# G32R501 register map
Vendor: Geehy Semiconductor Co., Ltd.; Series: G32R5; File version: 1.0
CPU: CM55 r0p1, little endian, MPU, FPU, double-precision FPU, DSP, VTOR, 4 interrupt priority bits
Registers are 32-bit, read-write, reset 0x0 unless marked. A register's access mark holds for its fields unless they carry their own. Offsets are from the block's base; [hi:lo] are bit positions; {n}, {i} and the like mark numbered series; 'fields as' and 'values as' point back to an identical list.

## CANA — CAN
Base 0x50002000
Same registers: CANB 0x50101800
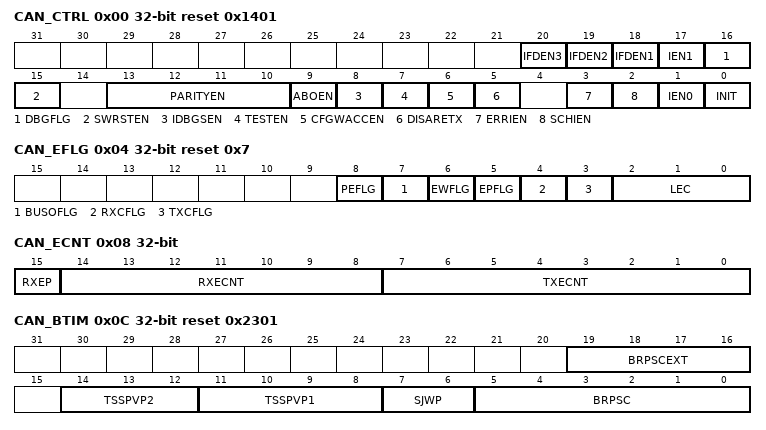
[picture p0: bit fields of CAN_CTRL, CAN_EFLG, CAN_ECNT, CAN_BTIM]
0x00 CAN_CTRL access per field reset 0x1401 — Control Register
  [20] IFDEN3 rw — IF3 DMA request line Enable
  [19] IFDEN2 rw — IF2 DMA request line Enable
  [18] IFDEN1 rw — IF1 DMA request line Enable
  [17] IEN1 rw — Interrupt line 1 Enable
  [16] DBGFLG ro — Debug Mode Flag
  [15] SWRSTEN rw — Software Reset Enable
  [13:10] PARITYEN rw — Parity Enable
  [9] ABOEN ro — Auto-Bus-On Enable
  [8] IDBGSEN rw — Interrupt Debug Support Enable
  [7] TESTEN rw — Test Mode Enable
  [6] CFGWACCEN rw — Configure write access Enable
  [5] DISARETX rw — Disable Automatic ReTransmit
  [3] ERRIEN rw — Error Interrupt Enable
  [2] SCHIEN rw — Status Change Interrupt Enable
  [1] IEN0 rw — Interrupt line 0 Enable
  [0] INIT rw — Initialization Mode
0x04 CAN_EFLG ro reset 0x7 — Error and Flag Register
  [8] PEFLG — Parity Error Flag
  [7] BUSOFLG — Bus-off Flag
  [6] EWFLG — Error Warning Flag
  [5] EPFLG — Error Passive Flag
  [4] RXCFLG — Reception completion flag
  [3] TXCFLG — Transmit completion flag
  [2:0] LEC — Last Error Code
0x08 CAN_ECNT ro — Error Counter Register
  [15] RXEP — Receive Error Passive
  [14:8] RXECNT — Receive Error Counter
  [7:0] TXECNT — Transmit Error Counter
0x0C CAN_BTIM reset 0x2301 — Bit time Register
  [19:16] BRPSCEXT — Baud Rate Prescaler Extension
  [14:12] TSSPVP2 — Time segment 2 before the sample point Valid programmed values
  [11:8] TSSPVP1 — Time segment 1 before the sample point Valid programmed values
  [7:6] SJWP — Synchronization Jump Width Valid programmed values
  [5:0] BRPSC — Baud Rate Prescaler
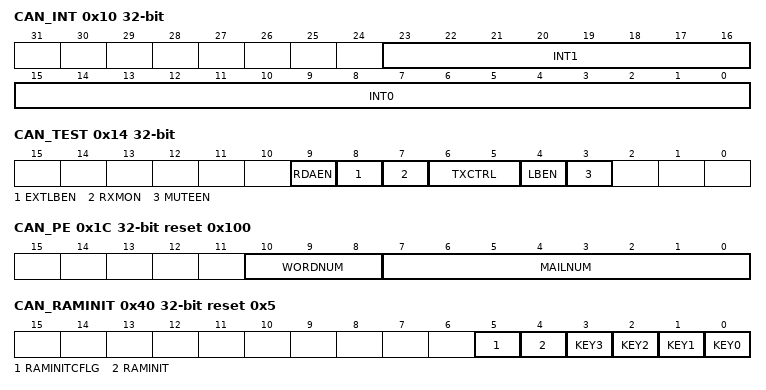
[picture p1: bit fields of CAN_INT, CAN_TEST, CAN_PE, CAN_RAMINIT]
0x10 CAN_INT ro — Interrupt Register
  [23:16] INT1 — Interrupt 1
  [15:0] INT0 — Interrupt 0
0x14 CAN_TEST access per field — Test Register
  [9] RDAEN rw — RAM Direct Access Enable
  [8] EXTLBEN rw — External Loop Back Mode Enable
  [7] RXMON ro — RX pin Monitors
  [6:5] TXCTRL rw — TX pin Control
  [4] LBEN rw — Loop Back Mode Enable
  [3] MUTEEN rw — Mute Mode Enable
0x1C CAN_PE reset 0x100 — parity error Register
  [10:8] WORDNUM — parity error Word number
  [7:0] MAILNUM — parity error Mailbox number
0x40 CAN_RAMINIT access per field reset 0x5 — RAM initialize Register
  [5] RAMINITCFLG ro — CAN Mailbox RAM initialization completion flag
  [4] RAMINIT rw — Initiate CAN Mailbox RAM initialization
  [n] KEY{n} rw (n=0..3)
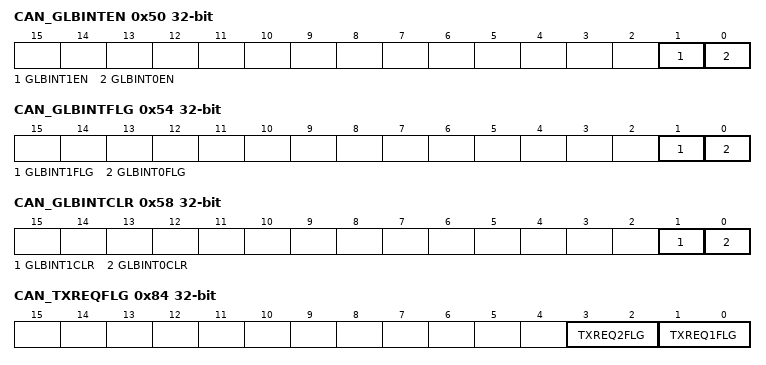
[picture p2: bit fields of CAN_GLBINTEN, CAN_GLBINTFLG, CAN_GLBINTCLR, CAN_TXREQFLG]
0x50 CAN_GLBINTEN — Global Interrupt Enable Register
  [1] GLBINT1EN — CANINT1 Global Interrupt Enable
  [0] GLBINT0EN — CANINT0 Global Interrupt Enable
0x54 CAN_GLBINTFLG ro — Global Interrupt Flag Register
  [1] GLBINT1FLG — CANINT1 Global Interrupt Flag
  [0] GLBINT0FLG — CANINT0 Global Interrupt Flag
0x58 CAN_GLBINTCLR wo — Global Interrupt Clear Register
  [1] GLBINT1CLR — CANINT1 Global Interrupt Flag Clear
  [0] GLBINT0CLR — CANINT0 Global Interrupt Flag Clear
0x80 CAN_ABOTMR — Auto-Bus-On Timer Register
  [31:0] ABOTMR — Auto-Bus-On Timer
0x84 CAN_TXREQFLG wo — Transmit Request Flag Register
  [3:2] TXREQ2FLG — Transmit Request Register 2 flag
  [1:0] TXREQ1FLG — Transmit Request Register 1 flag
0x88 CAN_TXREQ wo — Transmit Request Register
  [31:0] TXREQEN — Transmit Request Enable
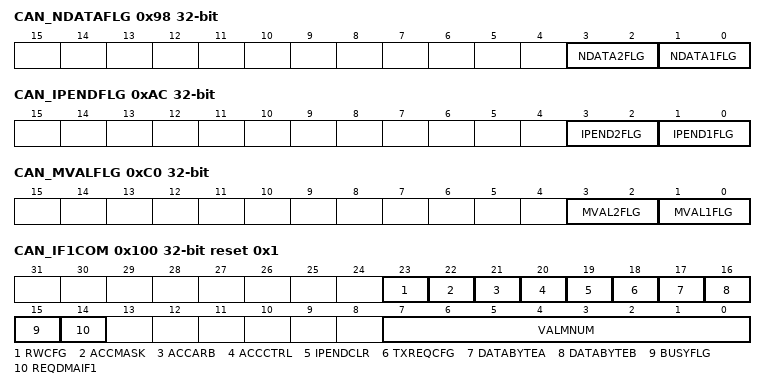
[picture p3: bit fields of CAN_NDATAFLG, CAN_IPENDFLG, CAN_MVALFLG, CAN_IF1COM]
0x98 CAN_NDATAFLG wo — New Data Flag Register
  [3:2] NDATA2FLG — New Data Register 2 flag
  [1:0] NDATA1FLG — New Data Register 1 flag
0x9C CAN_NDATA wo — New Data Register
  [31:0] NDATA — New Data
0xAC CAN_IPENDFLG wo — Interrupt Pending Flag Register
  [3:2] IPEND2FLG — Interrupt Pending Register 2 flag
  [1:0] IPEND1FLG — Interrupt Pending Register 1 flag
0xB0 CAN_IPEND wo — Interrupt Pending Register
  [31:0] IPEND — Interrupt Pending
0xC0 CAN_MVALFLG wo — Message Valid Flag Register
  [3:2] MVAL2FLG — Message Valid Register 2 flag
  [1:0] MVAL1FLG — Message Valid Register 1 flag
0xC4 CAN_MVAL wo — Message Valid Register
  [31:0] MVAL — Mailbox Valid
0xD8 CAN_INTMAIL — Interrupt mailbox Register
  [31:0] INTMAIL — Interrupt mailbox
0x100 CAN_IF1COM access per field reset 0x1 — IF1 Command Register
  [23] RWCFG rw — Read/Write function Configure
  [22] ACCMASK rw — Access Mask
  [21] ACCARB rw — Access Arbitration
  [20] ACCCTRL rw — Access control
  [19] IPENDCLR rw — Interrupt Pending Clear
  [18] TXREQCFG rw — Transmit Request/ New Data Configure
  [17] DATABYTEA rw — Access Data Bytes 0-3
  [16] DATABYTEB rw — Access Data Bytes 4-7
  [15] BUSYFLG ro — Busy Flag
  [14] REQDMAIF1 rw — Request DMA after IF1 update
  [7:0] VALMNUM rw — Valid Mailbox Number
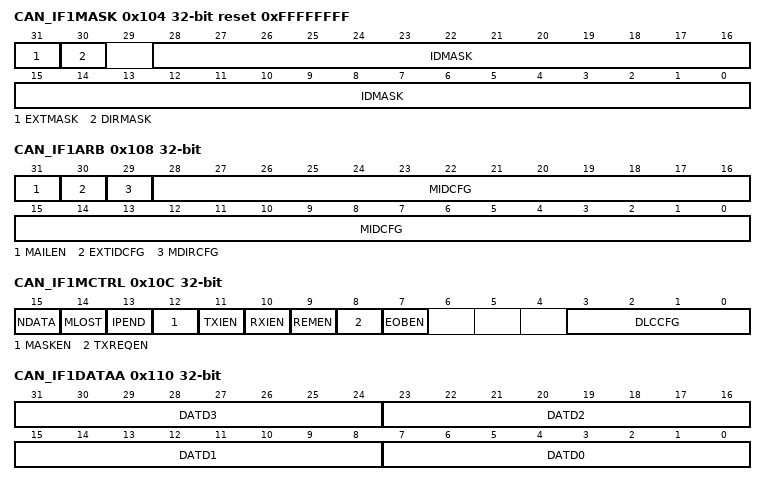
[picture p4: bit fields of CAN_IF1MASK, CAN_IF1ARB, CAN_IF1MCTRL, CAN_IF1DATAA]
0x104 CAN_IF1MASK reset 0xFFFFFFFF — IF1 Mask Register
  [31] EXTMASK — Extended Identifier Mask
  [30] DIRMASK — Message Direction Mask
  [28:0] IDMASK — Identifier Mask
0x108 CAN_IF1ARB — IF1 Arbitration Register
  [31] MAILEN — mailbox enable
  [30] EXTIDCFG — Extended Identifier Configure
  [29] MDIRCFG — Message Direction Configure
  [28:0] MIDCFG — Message Identifier Configure
0x10C CAN_IF1MCTRL — IF1 Message Control Register
  [15] NDATA — New Data
  [14] MLOST — Message Lost
  [13] IPEND — Interrupt Pending
  [12] MASKEN — Mask Enable
  [11] TXIEN — Transmit Interrupt Enable
  [10] RXIEN — Receive Interrupt Enable
  [9] REMEN — Remote Enable
  [8] TXREQEN — Transmit Request Enable
  [7] EOBEN — End of Block Enable
  [3:0] DLCCFG — Data Length Code Configure
0x110 CAN_IF1DATAA — IF1 data A Register
  [8n+7:8n] DATD{n} (n=0..3) — Data Byte {n}
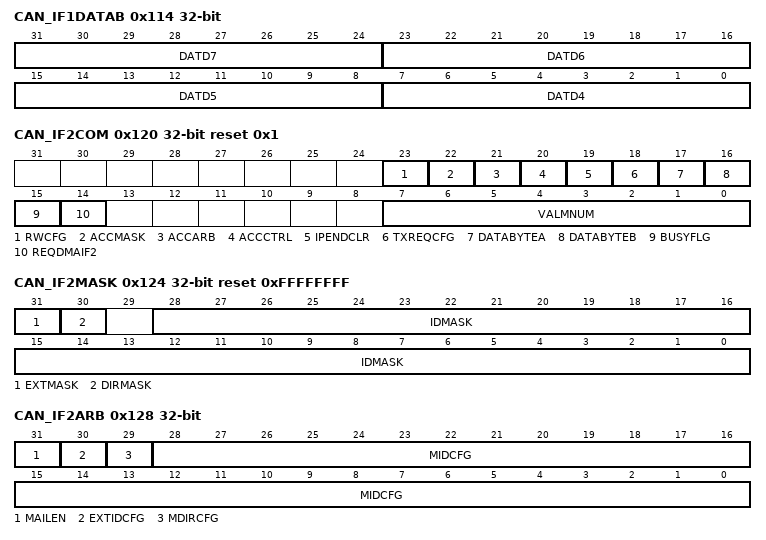
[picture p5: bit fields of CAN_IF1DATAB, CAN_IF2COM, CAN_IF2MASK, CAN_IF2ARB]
0x114 CAN_IF1DATAB — IF1 data B Register
  [8n-25:8n-32] DATD{n} (n=4..7) — Data Byte {n}
0x120 CAN_IF2COM access per field reset 0x1 — IF2 Command Register
  [23] RWCFG rw — Read/Write function Configure
  [22] ACCMASK rw — Access Mask
  [21] ACCARB rw — Access Arbitration
  [20] ACCCTRL rw — Access control
  [19] IPENDCLR rw — Interrupt Pending Clear
  [18] TXREQCFG rw — Transmit Request/ New Data Configure
  [17] DATABYTEA rw — Access Data Bytes 0-3
  [16] DATABYTEB rw — Access Data Bytes 4-7
  [15] BUSYFLG ro — Busy Flag
  [14] REQDMAIF2 rw — Request DMA after IF2 update
  [7:0] VALMNUM rw — Valid Mailbox Number
0x124 CAN_IF2MASK reset 0xFFFFFFFF — IF2 Mask Register
  fields as CAN_IF1MASK
0x128 CAN_IF2ARB — IF2 Arbitration Register
  fields as CAN_IF1ARB
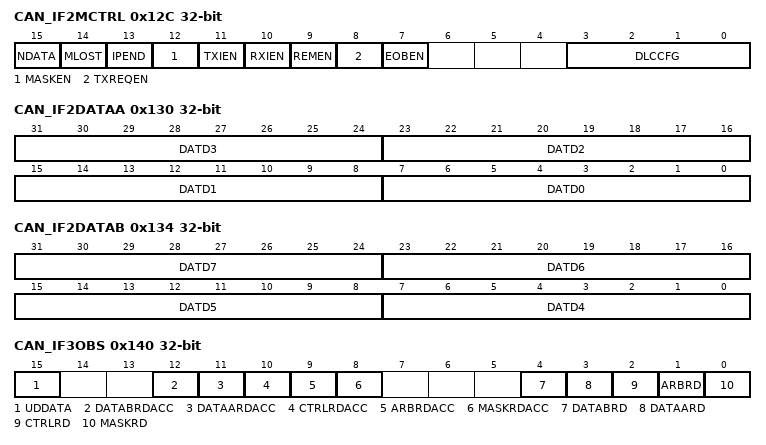
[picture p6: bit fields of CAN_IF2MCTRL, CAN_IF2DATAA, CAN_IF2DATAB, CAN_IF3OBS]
0x12C CAN_IF2MCTRL — IF2 Message Control Register
  fields as CAN_IF1MCTRL
0x130 CAN_IF2DATAA — IF2 data A Register
  [8n+7:8n] DATD{n} (n=0..3) — Data Byte {n}
0x134 CAN_IF2DATAB — IF2 data B Register
  [8n-25:8n-32] DATD{n} (n=4..7) — Data Byte {n}
0x140 CAN_IF3OBS access per field — IF3 Observation register
  [15] UDDATA ro — Update Data
  [12] DATABRDACC ro — Data B read access status
  [11] DATAARDACC ro — Data A read access status
  [10] CTRLRDACC ro — Control bits read access status
  [9] ARBRDACC ro — Arbitration data read access status
  [8] MASKRDACC ro — Mask data read access status
  [4] DATABRD rw — Data B read
  [3] DATAARD rw — Data A read
  [2] CTRLRD rw — Control bits read
  [1] ARBRD rw — Arbitration data read
  [0] MASKRD rw — Mask data read
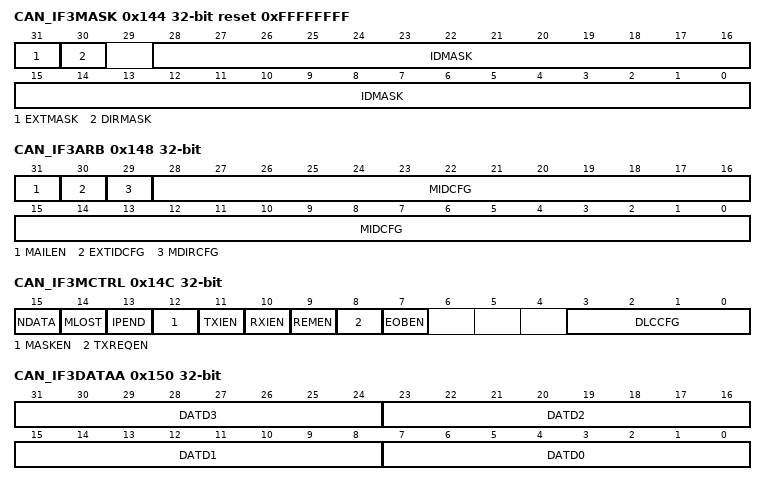
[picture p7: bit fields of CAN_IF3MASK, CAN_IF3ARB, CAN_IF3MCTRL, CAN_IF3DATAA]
0x144 CAN_IF3MASK ro reset 0xFFFFFFFF — IF3 Mask Register
  fields as CAN_IF1MASK
0x148 CAN_IF3ARB ro — IF3 Arbitration Register
  fields as CAN_IF1ARB
0x14C CAN_IF3MCTRL ro — IF3 Message Control Register
  fields as CAN_IF1MCTRL
0x150 CAN_IF3DATAA ro — IF3 data A Register
  [8n+7:8n] DATD{n} (n=0..3) — Data Byte {n}
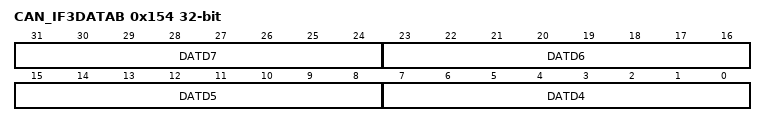
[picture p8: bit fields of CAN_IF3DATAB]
0x154 CAN_IF3DATAB ro — IF3 data B Register
  [8n-25:8n-32] DATD{n} (n=4..7) — Data Byte {n}
0x160 CAN_IF3UDEN — IF3 Update enable Register
  [31:0] UDEN — IF3 Update Enable
